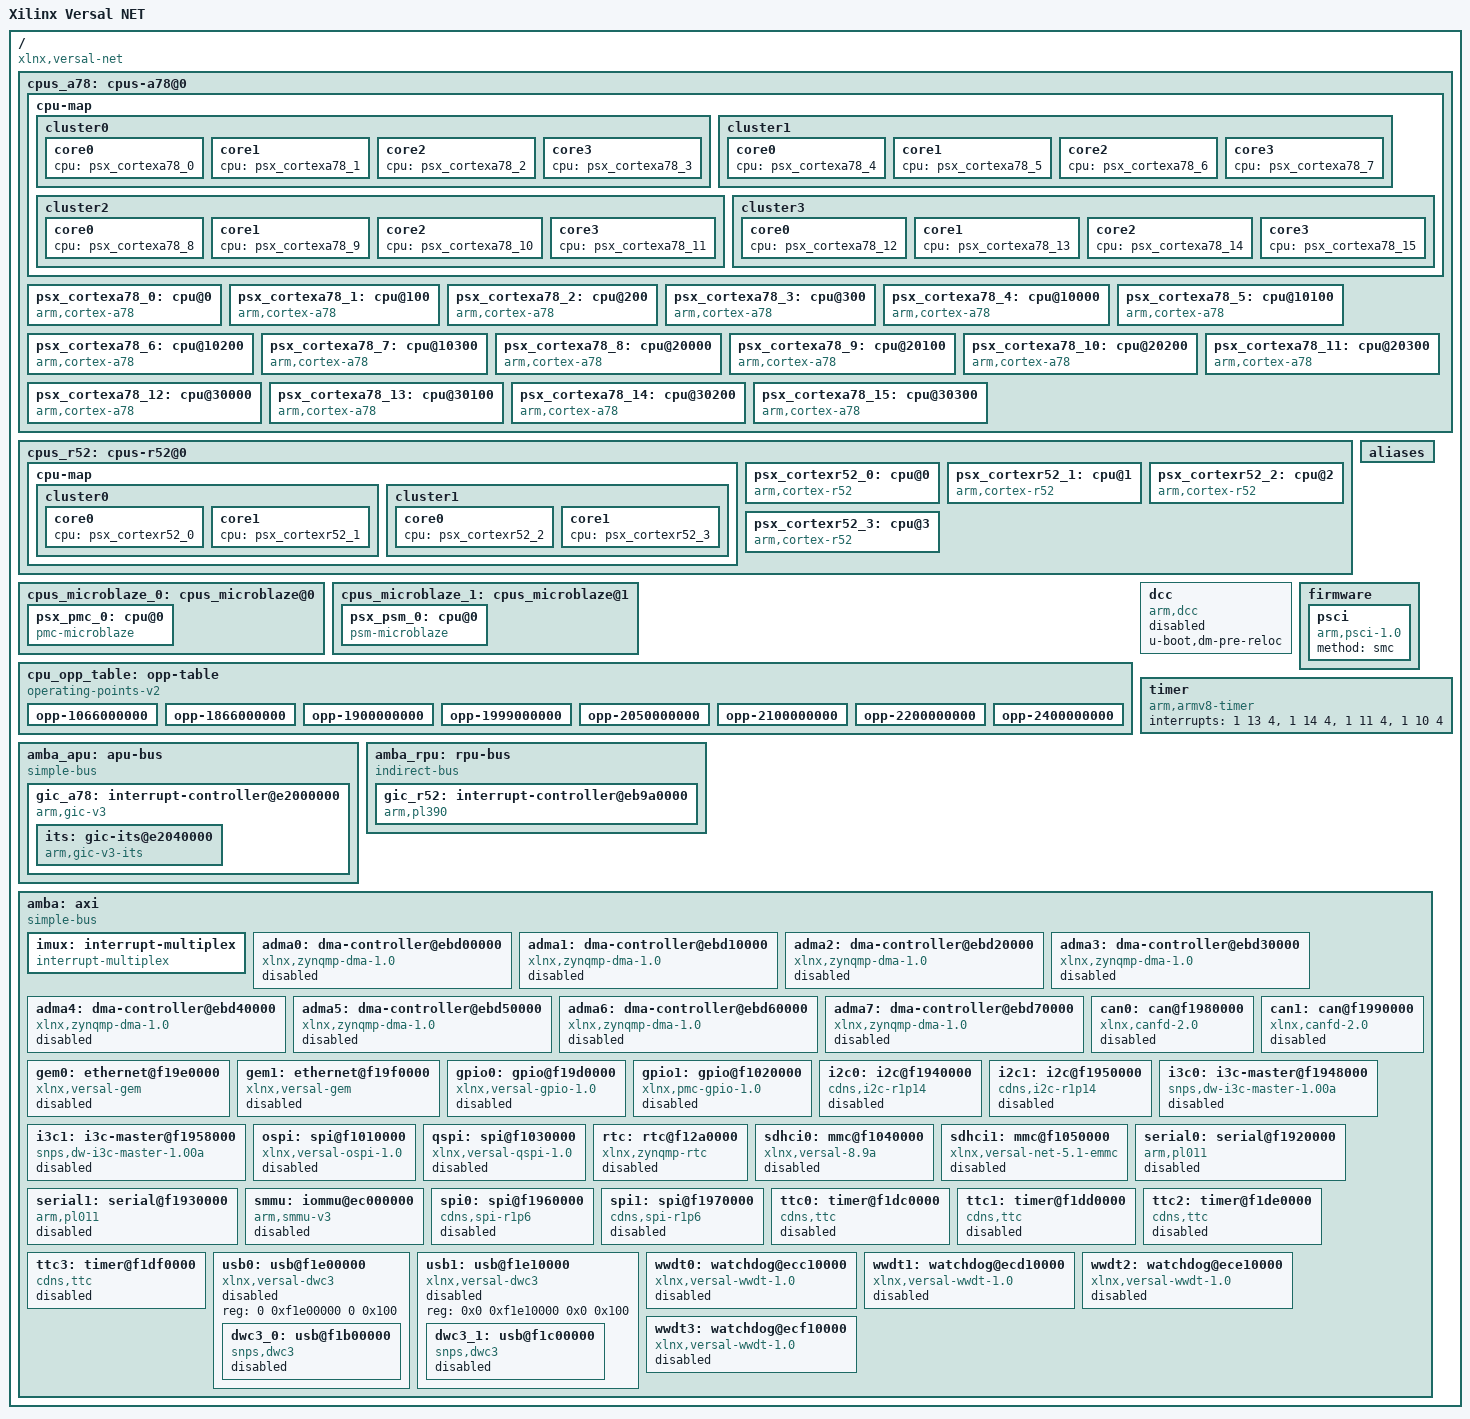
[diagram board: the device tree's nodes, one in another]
// SPDX-License-Identifier: GPL-2.0
/*
 * dts file for Xilinx Versal NET
 *
 * Copyright (C) 2022, Xilinx, Inc.
 * Copyright (C) 2022, Advanced Micro Devices, Inc.
 *
 * Michal Simek <michal.simek@amd.com>
 */

/ {
	compatible = "xlnx,versal-net";
	model = "Xilinx Versal NET";
	#address-cells = <2>;
	#size-cells = <2>;
	interrupt-parent = <&imux>;

	cpus_a78: cpus-a78@0 {
		#address-cells = <1>;
		#size-cells = <0>;
		cpu-map {
			cluster0 {
				core0 {
					cpu = <&psx_cortexa78_0>;
				};
				core1 {
					cpu = <&psx_cortexa78_1>;
				};
				core2 {
					cpu = <&psx_cortexa78_2>;
				};
				core3 {
					cpu = <&psx_cortexa78_3>;
				};
			};

			cluster1 {
				core0 {
					cpu = <&psx_cortexa78_4>;
				};

				core1 {
					cpu = <&psx_cortexa78_5>;
				};

				core2 {
					cpu = <&psx_cortexa78_6>;
				};

				core3 {
					cpu = <&psx_cortexa78_7>;
				};
			};
			cluster2 {
				core0 {
					cpu = <&psx_cortexa78_8>;
				};

				core1 {
					cpu = <&psx_cortexa78_9>;
				};

				core2 {
					cpu = <&psx_cortexa78_10>;
				};

				core3 {
					cpu = <&psx_cortexa78_11>;
				};
			};
			cluster3 {
				core0 {
					cpu = <&psx_cortexa78_12>;
				};

				core1 {
					cpu = <&psx_cortexa78_13>;
				};

				core2 {
					cpu = <&psx_cortexa78_14>;
				};

				core3 {
					cpu = <&psx_cortexa78_15>;
				};
			};

		};

		psx_cortexa78_0: cpu@0 {
			compatible = "arm,cortex-a78";
			device_type = "cpu";
			enable-method = "psci";
			reg = <0>;
            operating-points-v2 = <&cpu_opp_table>;
		};
		psx_cortexa78_1: cpu@100 {
			compatible = "arm,cortex-a78";
			device_type = "cpu";
			enable-method = "psci";
			reg = <0x100>;
            operating-points-v2 = <&cpu_opp_table>;
		};
		psx_cortexa78_2: cpu@200 {
			compatible = "arm,cortex-a78";
			device_type = "cpu";
			enable-method = "psci";
			reg = <0x200>;
            operating-points-v2 = <&cpu_opp_table>;
		};
		psx_cortexa78_3: cpu@300 {
			compatible = "arm,cortex-a78";
			device_type = "cpu";
			enable-method = "psci";
			reg = <0x300>;
            operating-points-v2 = <&cpu_opp_table>;
		};
		psx_cortexa78_4: cpu@10000 {
			compatible = "arm,cortex-a78";
			device_type = "cpu";
			enable-method = "psci";
			reg = <0x10000>;
            operating-points-v2 = <&cpu_opp_table>;
		};
		psx_cortexa78_5: cpu@10100 {
			compatible = "arm,cortex-a78";
			device_type = "cpu";
			enable-method = "psci";
			reg = <0x10100>;
            operating-points-v2 = <&cpu_opp_table>;
		};
		psx_cortexa78_6: cpu@10200 {
			compatible = "arm,cortex-a78";
			device_type = "cpu";
			enable-method = "psci";
			reg = <0x10200>;
            operating-points-v2 = <&cpu_opp_table>;
		};
		psx_cortexa78_7: cpu@10300 {
			compatible = "arm,cortex-a78";
			device_type = "cpu";
			enable-method = "psci";
			reg = <0x10300>;
            operating-points-v2 = <&cpu_opp_table>;
		};
		psx_cortexa78_8: cpu@20000 {
			compatible = "arm,cortex-a78";
			device_type = "cpu";
			enable-method = "psci";
			reg = <0x20000>;
            operating-points-v2 = <&cpu_opp_table>;
		};
		psx_cortexa78_9: cpu@20100 {
			compatible = "arm,cortex-a78";
			device_type = "cpu";
			enable-method = "psci";
			reg = <0x20100>;
            operating-points-v2 = <&cpu_opp_table>;
		};
		psx_cortexa78_10: cpu@20200 {
			compatible = "arm,cortex-a78";
			device_type = "cpu";
			enable-method = "psci";
			reg = <0x20200>;
            operating-points-v2 = <&cpu_opp_table>;
		};
		psx_cortexa78_11: cpu@20300 {
			compatible = "arm,cortex-a78";
			device_type = "cpu";
			enable-method = "psci";
			reg = <0x20300>;
            operating-points-v2 = <&cpu_opp_table>;
		};
		psx_cortexa78_12: cpu@30000 {
			compatible = "arm,cortex-a78";
			device_type = "cpu";
			enable-method = "psci";
			reg = <0x30000>;
            operating-points-v2 = <&cpu_opp_table>;
		};
		psx_cortexa78_13: cpu@30100 {
			compatible = "arm,cortex-a78";
			device_type = "cpu";
			enable-method = "psci";
			reg = <0x30100>;
            operating-points-v2 = <&cpu_opp_table>;
		};
		psx_cortexa78_14: cpu@30200 {
			compatible = "arm,cortex-a78";
			device_type = "cpu";
			enable-method = "psci";
			reg = <0x30200>;
            operating-points-v2 = <&cpu_opp_table>;
		};
		psx_cortexa78_15: cpu@30300 {
			compatible = "arm,cortex-a78";
			device_type = "cpu";
			enable-method = "psci";
			reg = <0x30300>;
            operating-points-v2 = <&cpu_opp_table>;
		};
	};

	cpus_r52: cpus-r52@0 {
		#address-cells = <1>;
		#size-cells = <0>;
		cpu-map {
			cluster0 {
				core0 {
					cpu = <&psx_cortexr52_0>;
				};
				core1 {
					cpu = <&psx_cortexr52_1>;
				};
			};

			cluster1 {
				core0 {
					cpu = <&psx_cortexr52_2>;
				};

				core1 {
					cpu = <&psx_cortexr52_3>;
				};
			};
		};

		psx_cortexr52_0: cpu@0 {
			compatible = "arm,cortex-r52";
			device_type = "cpu";
			reg = <0x0>;
			operating-points-v2 = <&cpu_opp_table>;
	    };

	    psx_cortexr52_1: cpu@1 {
			compatible = "arm,cortex-r52";
			device_type = "cpu";
			reg = <0x1>;
			operating-points-v2 = <&cpu_opp_table>;
		};

		psx_cortexr52_2: cpu@2 {
	        compatible = "arm,cortex-r52";
	        device_type = "cpu";
	        reg = <0x2>;
	        operating-points-v2 = <&cpu_opp_table>;
	    };

	    psx_cortexr52_3: cpu@3 {
	        compatible = "arm,cortex-r52";
	        device_type = "cpu";
	        reg = <0x3>;
	        operating-points-v2 = <&cpu_opp_table>;
	    };
	};

	cpus_microblaze_0: cpus_microblaze@0 {
		#address-cells = <1>;
		#size-cells = <0>;
        psx_pmc_0: cpu@0 {
            compatible = "pmc-microblaze";
            device_type = "cpu";
            reg = <0x0>;
            operating-points-v2 = <&cpu_opp_table>;
        };
	};

	cpus_microblaze_1: cpus_microblaze@1 {
		#address-cells = <1>;
		#size-cells = <0>;
        psx_psm_0: cpu@0 {
	        compatible = "psm-microblaze";
	        device_type = "cpu";
	        reg = <0x1>;
	        operating-points-v2 = <&cpu_opp_table>;
        };
	};


	cpu_opp_table: opp-table {
		compatible = "operating-points-v2";
		opp-1066000000 {
			opp-hz = /bits/ 64 <1066000000>;
			opp-microvolt = <1000000>;
			clock-latency-ns = <500000>;
		};
		opp-1866000000 {
			opp-hz = /bits/ 64 <1866000000>;
			opp-microvolt = <1000000>;
			clock-latency-ns = <500000>;
		};
		opp-1900000000 {
			opp-hz = /bits/ 64 <1900000000>;
			opp-microvolt = <1000000>;
			clock-latency-ns = <500000>;
		};
		opp-1999000000 {
			opp-hz = /bits/ 64 <1999000000>;
			opp-microvolt = <1000000>;
			clock-latency-ns = <500000>;
		};
		opp-2050000000 {
			opp-hz = /bits/ 64 <2050000000>;
			opp-microvolt = <1000000>;
			clock-latency-ns = <500000>;
		};
		opp-2100000000 {
			opp-hz = /bits/ 64 <2100000000>;
			opp-microvolt = <1000000>;
			clock-latency-ns = <500000>;
		};
		opp-2200000000 {
			opp-hz = /bits/ 64 <2200000000>;
			opp-microvolt = <1000000>;
			clock-latency-ns = <500000>;
		};
		opp-2400000000 {
			opp-hz = /bits/ 64 <2400000000>;
			opp-microvolt = <1000000>;
			clock-latency-ns = <500000>;
        };
    };
	aliases {
		serial0 = &serial0;
		serial1 = &serial1;
		serial2 = &dcc;
		mmc0 = &sdhci0;
		mmc1 = &sdhci1;
		i2c0 = &i2c0;
		i2c1 = &i2c1;
		rtc = &rtc;
		usb0 = &usb0;
		usb1 = &usb1;
		spi0 = &ospi;
		spi1 = &qspi;
	};

	dcc: dcc {
		compatible = "arm,dcc";
		status = "disabled";
		u-boot,dm-pre-reloc;
	};

	firmware {
		psci {
			compatible = "arm,psci-1.0";
			method = "smc";
		};
	};

	timer: timer {
		compatible = "arm,armv8-timer";
		interrupts = <1 13 4>, <1 14 4>, <1 11 4>, <1 10 4>; /* FIXME 3rd cell */
	};

	amba_apu: apu-bus {
		compatible = "simple-bus";
		#address-cells = <2>;
		#size-cells = <2>;
		ranges;
		interrupt-parent = <&gic_a78>;
		u-boot,dm-pre-reloc;

		gic_a78: interrupt-controller@e2000000 {
			compatible = "arm,gic-v3";
			#interrupt-cells = <3>;
			#address-cells = <2>;
			#size-cells = <2>;
			ranges;
			reg = <0 0xe2000000 0 0x10000>,
			      <0 0xe2060000 0 0x200000>;
			interrupt-controller;
			interrupt-parent = <&gic_a78>;
			interrupts = <1 9 4>;

			its: gic-its@e2040000 {
				compatible = "arm,gic-v3-its";
				msi-controller;
				msi-cells = <1>;
				reg = <0 0xe2040000 0 0x20000>;
		        };
		};
	};

	amba_rpu: rpu-bus {
		compatible = "indirect-bus";
		#address-cells = <0x2>;
		#size-cells = <0x2>;
		ranges;
		interrupt-parent = <&gic_r52>;
		u-boot,dm-pre-reloc;

		gic_r52: interrupt-controller@eb9a0000 {
			compatible = "arm,pl390";
			#interrupt-cells = <3>;
			interrupt-controller;
			reg = <0x0 0xeb9a0000 0x0 0x1000>;
		};
	};



	amba: axi {
		compatible = "simple-bus";
		u-boot,dm-pre-reloc;
		#address-cells = <2>;
		#size-cells = <2>;
		ranges;
		interrupt-parent = <&imux>;

		/* Proxy Interrupt Controller */
		imux: interrupt-multiplex {
			compatible = "interrupt-multiplex";
			#address-cells = <0x0>;
			#interrupt-cells = <3>;
			interrupt-controller;
			interrupt-parent = <&gic_a78>, <&gic_r52>;
			/* mask for address cells, mask for interrupt cells of the children */
			interrupt-map-mask = <0x0 0xffff 0x0>;
			/* 1:1 mapping of all interrupts to gic_a78 and gic_r52 */
			/* child address cells, child interrupt cells, parent, parent interrupt cells */
			interrupt-map = <0x0 0x14 0x0 &gic_a78 0x0 0x14 0x4>,
					<0x0 0x15 0x0 &gic_a78 0x0 0x15 0x4>,
					<0x0 0x16 0x0 &gic_a78 0x0 0x16 0x4>,
					<0x0 0x17 0x0 &gic_a78 0x0 0x17 0x4>,
					<0x0 0x18 0x0 &gic_a78 0x0 0x18 0x4>,
					<0x0 0x19 0x0 &gic_a78 0x0 0x19 0x4>,
					<0x0 0x1a 0x0 &gic_a78 0x0 0x1a 0x4>,
					<0x0 0x1b 0x0 &gic_a78 0x0 0x1b 0x4>,
					<0x0 0x1c 0x0 &gic_a78 0x0 0x1c 0x4>,
					<0x0 0x1d 0x0 &gic_a78 0x0 0x1d 0x4>,
					<0x0 0x21 0x0 &gic_a78 0x0 0x21 0x4>,
					<0x0 0x22 0x0 &gic_a78 0x0 0x22 0x4>,
					<0x0 0x26 0x0 &gic_a78 0x0 0x26 0x4>,
					<0x0 0x27 0x0 &gic_a78 0x0 0x27 0x4>,
					<0x0 0x29 0x0 &gic_a78 0x0 0x29 0x4>,
					<0x0 0x2b 0x0 &gic_a78 0x0 0x2b 0x4>,
					<0x0 0x2c 0x0 &gic_a78 0x0 0x2c 0x4>,
					<0x0 0x2d 0x0 &gic_a78 0x0 0x2d 0x4>,
					<0x0 0x2e 0x0 &gic_a78 0x0 0x2e 0x4>,
					<0x0 0x2f 0x0 &gic_a78 0x0 0x2f 0x4>,
					<0x0 0x30 0x0 &gic_a78 0x0 0x30 0x4>,
					<0x0 0x31 0x0 &gic_a78 0x0 0x31 0x4>,
					<0x0 0x32 0x0 &gic_a78 0x0 0x32 0x4>,
					<0x0 0x33 0x0 &gic_a78 0x0 0x33 0x4>,
					<0x0 0x34 0x0 &gic_a78 0x0 0x34 0x4>,
					<0x0 0x35 0x0 &gic_a78 0x0 0x35 0x4>,
					<0x0 0x36 0x0 &gic_a78 0x0 0x36 0x4>,
					<0x0 0x48 0x0 &gic_a78 0x0 0x48 0x4>,
					<0x0 0x49 0x0 &gic_a78 0x0 0x49 0x4>,
					<0x0 0x4a 0x0 &gic_a78 0x0 0x4a 0x4>,
					<0x0 0x4b 0x0 &gic_a78 0x0 0x4b 0x4>,
					<0x0 0x4c 0x0 &gic_a78 0x0 0x4c 0x4>,
					<0x0 0x4d 0x0 &gic_a78 0x0 0x4d 0x4>,
					<0x0 0x4e 0x0 &gic_a78 0x0 0x4e 0x4>,
					<0x0 0x4f 0x0 &gic_a78 0x0 0x4f 0x4>,
					<0x0 0x62 0x0 &gic_a78 0x0 0x62 0x4>,
					<0x0 0x63 0x0 &gic_a78 0x0 0x63 0x4>,
					<0x0 0xa9 0x0 &gic_a78 0x0 0xa9 0x4>,
					<0x0 0xb4 0x0 &gic_a78 0x0 0xb4 0x4>,
					<0x0 0xb5 0x0 &gic_a78 0x0 0xb5 0x4>,
					<0x0 0xb6 0x0 &gic_a78 0x0 0xb6 0x4>,
					<0x0 0xb7 0x0 &gic_a78 0x0 0xb7 0x4>,
					<0x0 0xb9 0x0 &gic_a78 0x0 0xb9 0x4>,
					<0x0 0xc8 0x0 &gic_a78 0x0 0xc8 0x4>,
					<0x0 0xc9 0x0 &gic_a78 0x0 0xc9 0x4>,
					<0x0 0x8b 0x0 &gic_a78 0x0 0x8b 0x1>,
					<0x0 0x8c 0x0 &gic_a78 0x0 0x8c 0x1>,
					<0x0 0x8f 0x0 &gic_a78 0x0 0x8f 0x1>,
					<0x0 0x90 0x0 &gic_a78 0x0 0x90 0x1>,
					<0x0 0x93 0x0 &gic_a78 0x0 0x93 0x1>,
					<0x0 0x94 0x0 &gic_a78 0x0 0x94 0x1>,
					<0x0 0xa4 0x0 &gic_a78 0x0 0xa4 0x1>,
					<0x0 0xa5 0x0 &gic_a78 0x0 0xa5 0x1>,
					<0x0 0x14 0x0 &gic_r52 0x0 0x14 0x4>,
					<0x0 0x15 0x0 &gic_r52 0x0 0x15 0x4>,
					<0x0 0x16 0x0 &gic_r52 0x0 0x16 0x4>,
					<0x0 0x17 0x0 &gic_r52 0x0 0x17 0x4>,
					<0x0 0x18 0x0 &gic_r52 0x0 0x18 0x4>,
					<0x0 0x19 0x0 &gic_r52 0x0 0x19 0x4>,
					<0x0 0x1a 0x0 &gic_r52 0x0 0x1a 0x4>,
					<0x0 0x1b 0x0 &gic_r52 0x0 0x1b 0x4>,
					<0x0 0x1c 0x0 &gic_r52 0x0 0x1c 0x4>,
					<0x0 0x1d 0x0 &gic_r52 0x0 0x1d 0x4>,
					<0x0 0x21 0x0 &gic_r52 0x0 0x21 0x4>,
					<0x0 0x22 0x0 &gic_r52 0x0 0x22 0x4>,
					<0x0 0x26 0x0 &gic_r52 0x0 0x26 0x4>,
					<0x0 0x27 0x0 &gic_r52 0x0 0x27 0x4>,
					<0x0 0x29 0x0 &gic_r52 0x0 0x29 0x4>,
					<0x0 0x2b 0x0 &gic_r52 0x0 0x2b 0x4>,
					<0x0 0x2c 0x0 &gic_r52 0x0 0x2c 0x4>,
					<0x0 0x2d 0x0 &gic_r52 0x0 0x2d 0x4>,
					<0x0 0x2e 0x0 &gic_r52 0x0 0x2e 0x4>,
					<0x0 0x2f 0x0 &gic_r52 0x0 0x2f 0x4>,
					<0x0 0x30 0x0 &gic_r52 0x0 0x30 0x4>,
					<0x0 0x31 0x0 &gic_r52 0x0 0x31 0x4>,
					<0x0 0x32 0x0 &gic_r52 0x0 0x32 0x4>,
					<0x0 0x33 0x0 &gic_r52 0x0 0x33 0x4>,
					<0x0 0x34 0x0 &gic_r52 0x0 0x34 0x4>,
					<0x0 0x35 0x0 &gic_r52 0x0 0x35 0x4>,
					<0x0 0x36 0x0 &gic_r52 0x0 0x36 0x4>,
					<0x0 0x48 0x0 &gic_r52 0x0 0x48 0x4>,
					<0x0 0x49 0x0 &gic_r52 0x0 0x49 0x4>,
					<0x0 0x4a 0x0 &gic_r52 0x0 0x4a 0x4>,
					<0x0 0x4b 0x0 &gic_r52 0x0 0x4b 0x4>,
					<0x0 0x4c 0x0 &gic_r52 0x0 0x4c 0x4>,
					<0x0 0x4d 0x0 &gic_r52 0x0 0x4d 0x4>,
					<0x0 0x4e 0x0 &gic_r52 0x0 0x4e 0x4>,
					<0x0 0x4f 0x0 &gic_r52 0x0 0x4f 0x4>,
					<0x0 0x62 0x0 &gic_r52 0x0 0x62 0x4>,
					<0x0 0x63 0x0 &gic_r52 0x0 0x63 0x4>,
					<0x0 0xa9 0x0 &gic_r52 0x0 0xa9 0x4>,
					<0x0 0xb4 0x0 &gic_r52 0x0 0xb4 0x4>,
					<0x0 0xb5 0x0 &gic_r52 0x0 0xb5 0x4>,
					<0x0 0xb6 0x0 &gic_r52 0x0 0xb6 0x4>,
					<0x0 0xb7 0x0 &gic_r52 0x0 0xb7 0x4>,
					<0x0 0xb9 0x0 &gic_r52 0x0 0xb9 0x4>,
					<0x0 0xc8 0x0 &gic_r52 0x0 0xc8 0x4>,
					<0x0 0xc9 0x0 &gic_r52 0x0 0xc9 0x4>,
					<0x0 0x8b 0x0 &gic_r52 0x0 0x8b 0x1>,
					<0x0 0x8c 0x0 &gic_r52 0x0 0x8c 0x1>,
					<0x0 0x8f 0x0 &gic_r52 0x0 0x8f 0x1>,
					<0x0 0x90 0x0 &gic_r52 0x0 0x90 0x1>,
					<0x0 0x93 0x0 &gic_r52 0x0 0x93 0x1>,
					<0x0 0x94 0x0 &gic_r52 0x0 0x94 0x1>,
					<0x0 0xa4 0x0 &gic_r52 0x0 0xa4 0x1>,
					<0x0 0xa5 0x0 &gic_r52 0x0 0xa5 0x1>;
		};


		adma0: dma-controller@ebd00000 {
			compatible = "xlnx,zynqmp-dma-1.0";
			status = "disabled";
			reg = <0 0xebd00000 0 0x1000>;
			interrupt-parent = <&imux>;
			interrupts = <0 72 4>;
			clock-names = "clk_main", "clk_apb";
			#dma-cells = <1>;
			xlnx,bus-width = <64>;
		};

		adma1: dma-controller@ebd10000 {
			compatible = "xlnx,zynqmp-dma-1.0";
			status = "disabled";
			reg = <0 0xebd10000 0 0x1000>;
			interrupt-parent = <&imux>;
			interrupts = <0 73 4>;
			clock-names = "clk_main", "clk_apb";
			#dma-cells = <1>;
			xlnx,bus-width = <64>;
		};

		adma2: dma-controller@ebd20000 {
			compatible = "xlnx,zynqmp-dma-1.0";
			status = "disabled";
			reg = <0 0xebd20000 0 0x1000>;
			interrupt-parent = <&imux>;
			interrupts = <0 74 4>;
			clock-names = "clk_main", "clk_apb";
			#dma-cells = <1>;
			xlnx,bus-width = <64>;
		};

		adma3: dma-controller@ebd30000 {
			compatible = "xlnx,zynqmp-dma-1.0";
			status = "disabled";
			reg = <0 0xebd30000 0 0x1000>;
			interrupt-parent = <&imux>;
			interrupts = <0 75 4>;
			clock-names = "clk_main", "clk_apb";
			#dma-cells = <1>;
			xlnx,bus-width = <64>;
		};

		adma4: dma-controller@ebd40000 {
			compatible = "xlnx,zynqmp-dma-1.0";
			status = "disabled";
			reg = <0 0xebd40000 0 0x1000>;
			interrupt-parent = <&imux>;
			interrupts = <0 76 4>;
			clock-names = "clk_main", "clk_apb";
			#dma-cells = <1>;
			xlnx,bus-width = <64>;
		};

		adma5: dma-controller@ebd50000 {
			compatible = "xlnx,zynqmp-dma-1.0";
			status = "disabled";
			reg = <0 0xebd50000 0 0x1000>;
			interrupt-parent = <&imux>;
			interrupts = <0 77 4>;
			clock-names = "clk_main", "clk_apb";
			#dma-cells = <1>;
			xlnx,bus-width = <64>;
		};

		adma6: dma-controller@ebd60000 {
			compatible = "xlnx,zynqmp-dma-1.0";
			status = "disabled";
			reg = <0 0xebd60000 0 0x1000>;
			interrupt-parent = <&imux>;
			interrupts = <0 78 4>;
			clock-names = "clk_main", "clk_apb";
			#dma-cells = <1>;
			xlnx,bus-width = <64>;
		};

		adma7: dma-controller@ebd70000 {
			compatible = "xlnx,zynqmp-dma-1.0";
			status = "disabled";
			reg = <0 0xebd70000 0 0x1000>;
			interrupt-parent = <&imux>;
			interrupts = <0 79 4>;
			clock-names = "clk_main", "clk_apb";
			#dma-cells = <1>;
			xlnx,bus-width = <64>;
		};

		can0: can@f1980000 {
			compatible = "xlnx,canfd-2.0";
			status = "disabled";
			reg = <0 0xf1980000 0 0x6000>;
			interrupt-parent = <&imux>;
			interrupts = <0 27 4>;
			clock-names = "can_clk", "s_axi_aclk";
			rx-fifo-depth = <64>;
			tx-mailbox-count = <32>;
		};

		can1: can@f1990000 {
			compatible = "xlnx,canfd-2.0";
			status = "disabled";
			reg = <0 0xf1990000 0 0x6000>;
			interrupt-parent = <&imux>;
			interrupts = <0 28 4>;
			clock-names = "can_clk", "s_axi_aclk";
			rx-fifo-depth = <64>;
			tx-mailbox-count = <32>;
		};

		gem0: ethernet@f19e0000 {
			compatible = "xlnx,versal-gem", "cdns,gem";
			status = "disabled";
			reg = <0 0xf19e0000 0 0x1000>;
			interrupt-parent = <&imux>;
			interrupts = <0 39 4>, <0 39 4>;
			clock-names = "pclk", "hclk", "tx_clk", "rx_clk",
			              "tsu_clk";
		};

		gem1: ethernet@f19f0000 {
			compatible = "xlnx,versal-gem", "cdns,gem";
			status = "disabled";
			reg = <0 0xf19f0000 0 0x1000>;
			interrupt-parent = <&imux>;
			interrupts = <0 41 4>, <0 41 4>;
			clock-names = "pclk", "hclk", "tx_clk", "rx_clk",
				      "tsu_clk";
		};

		gpio0: gpio@f19d0000 {
			compatible = "xlnx,versal-gpio-1.0";
			status = "disabled";
			reg = <0 0xf19d0000 0 0x1000>;
			interrupt-parent = <&imux>;
			interrupts = <0 20 4>;
			#gpio-cells = <2>;
			gpio-controller;
			#interrupt-cells = <2>;
			interrupt-controller;
		};

		gpio1: gpio@f1020000 {
			compatible = "xlnx,pmc-gpio-1.0";
			status = "disabled";
			reg = <0 0xf1020000 0 0x1000>;
			interrupt-parent = <&imux>;
			interrupts = <0 180 4>;
			#gpio-cells = <2>;
			gpio-controller;
			#interrupt-cells = <2>;
			interrupt-controller;
		};

		i2c0: i2c@f1940000 {
			compatible = "cdns,i2c-r1p14";
			status = "disabled";
			reg = <0 0xf1940000 0 0x1000>;
			interrupt-parent = <&imux>;
			interrupts = <0 21 4>;
			clock-frequency = <400000>;
			#address-cells = <1>;
			#size-cells = <0>;
		};

		i2c1: i2c@f1950000 {
			compatible = "cdns,i2c-r1p14";
			status = "disabled";
			reg = <0 0xf1950000 0 0x1000>;
			interrupt-parent = <&imux>;
			interrupts = <0 22 4>;
			clock-frequency = <400000>;
			#address-cells = <1>;
			#size-cells = <0>;
		};

		i3c0: i3c-master@f1948000 {
			compatible = "snps,dw-i3c-master-1.00a";
			status = "disabled";
			reg = <0 0xf1948000 0 0x1000>;
			#address-cells = <3>;
			#size-cells = <0>;
			interrupt-parent = <&imux>;
			interrupts = <0 21 4>;
		};

		i3c1: i3c-master@f1958000 {
			compatible = "snps,dw-i3c-master-1.00a";
			status = "disabled";
			reg = <0 0xf1958000 0 0x1000>;
			#address-cells = <3>;
			#size-cells = <0>;
			interrupt-parent = <&imux>;
			interrupts = <0 22 4>;
		};

		ospi: spi@f1010000 {
			compatible = "xlnx,versal-ospi-1.0", "cdns,qspi-nor";
			status = "disabled";
			reg = <0 0xf1010000 0 0x10000>,
			      <0 0xc0000000 0 0x20000000>;
			interrupt-parent = <&imux>;
			interrupts = <0 182 4>;
			cdns,fifo-depth = <256>;
			cdns,fifo-width = <4>;
			cdns,is-dma = <1>; /* u-boot specific */
			/* cdns,is-stig-pgm = <1>; - unused - checking with Sai */
			cdns,trigger-address = <0xc0000000>;
		};

		qspi: spi@f1030000 {
			compatible = "xlnx,versal-qspi-1.0";
			status = "disabled";
			reg = <0 0xf1030000 0 0x1000>; /* missing one more reg range - checking with Sai */
			interrupt-parent = <&imux>;
			interrupts = <0 183 4>;
			clock-names = "ref_clk", "pclk";
		};

		rtc: rtc@f12a0000 {
			compatible = "xlnx,zynqmp-rtc";
			status = "disabled";
			reg = <0 0xf12a0000 0 0x100>;
			interrupt-parent = <&imux>;
			interrupts = <0 200 4>, <0 201 4>;
			interrupt-names = "alarm", "sec";
			calibration = <0x8000>;
		};

		sdhci0: mmc@f1040000 {
			compatible = "xlnx,versal-8.9a", "arasan,sdhci-8.9a";
			status = "disabled";
			reg = <0 0xf1040000 0 0x10000>;
			interrupt-parent = <&imux>;
			interrupts = <0 184 4>;
			clock-names = "clk_xin", "clk_ahb", "gate";
			#clock-cells = <1>;
			clock-output-names = "clk_out_sd0", "clk_in_sd0";
		};

		sdhci1: mmc@f1050000 {
			compatible = "xlnx,versal-net-5.1-emmc",
				     "arasan,sdhci-8.9a";
			status = "disabled";
			reg = <0 0xf1050000 0 0x10000>;
			interrupt-parent = <&imux>;
			interrupts = <0 186 4>;
			clock-names = "clk_xin", "clk_ahb", "gate";
			#clock-cells = <1>;
			clock-output-names = "clk_out_sd1", "clk_in_sd1";
		};

		serial0: serial@f1920000 {
			u-boot,dm-pre-reloc;
			compatible = "arm,pl011", "arm,primecell";
			status = "disabled";
			reg = <0 0xf1920000 0 0x1000>;
			interrupt-parent = <&imux>;
			interrupts = <0 25 4>;
			reg-io-width = <4>;
			clock-names = "uartclk", "apb_pclk";
			current-speed = <115200>;
		};

		serial1: serial@f1930000 {
			u-boot,dm-pre-reloc;
			compatible = "arm,pl011", "arm,primecell";
			status = "disabled";
			reg = <0 0xf1930000 0 0x1000>;
			interrupt-parent = <&imux>;
			interrupts = <0 26 4>;
			reg-io-width = <4>;
			clock-names = "uartclk", "apb_pclk";
			current-speed = <115200>;
		};

		smmu: iommu@ec000000 {
			compatible = "arm,smmu-v3";
			status = "disabled";
			reg = <0 0xec000000 0 0x40000>;
			#iommu-cells = <1>;
			interrupt-names = "combined";
			interrupt-parent = <&imux>;
			interrupts = <0 169 4>;
			dma-coherent;
		};

		spi0: spi@f1960000 {
			compatible = "cdns,spi-r1p6";
			status = "disabled";
			interrupt-parent = <&imux>;
			interrupts = <0 23 4>;
			reg = <0 0xf1960000 0 0x1000>;
			clock-names = "ref_clk", "pclk";
		};

		spi1: spi@f1970000 {
			compatible = "cdns,spi-r1p6";
			status = "disabled";
			interrupt-parent = <&imux>;
			interrupts = <0 24 4>;
			reg = <0 0xf1970000 0 0x1000>;
			clock-names = "ref_clk", "pclk";
		};

		ttc0: timer@f1dc0000 {
			compatible = "cdns,ttc";
			status = "disabled";
			interrupt-parent = <&imux>;
			interrupts = <0 43 4>, <0 44 4>, <0 45 4>;
			timer-width = <32>;
			reg = <0x0 0xf1dc0000 0x0 0x1000>;
		};

		ttc1: timer@f1dd0000 {
			compatible = "cdns,ttc";
			status = "disabled";
			interrupt-parent = <&imux>;
			interrupts = <0 46 4>, <0 47 4>, <0 48 4>;
			timer-width = <32>;
			reg = <0x0 0xf1dd0000 0x0 0x1000>;
		};

		ttc2: timer@f1de0000 {
			compatible = "cdns,ttc";
			status = "disabled";
			interrupt-parent = <&imux>;
			interrupts = <0 49 4>, <0 50 4>, <0 51 4>;
			timer-width = <32>;
			reg = <0x0 0xf1de0000 0x0 0x1000>;
		};

		ttc3: timer@f1df0000 {
			compatible = "cdns,ttc";
			status = "disabled";
			interrupt-parent = <&imux>;
			interrupts = <0 52 4>, <0 53 4>, <0 54 4>;
			timer-width = <32>;
			reg = <0x0 0xf1df0000 0x0 0x1000>;
		};

		usb0: usb@f1e00000 {
			compatible = "xlnx,versal-dwc3";
			status = "disabled";
			reg = <0 0xf1e00000 0 0x100>;
			clock-names = "bus_clk", "ref_clk";
			ranges;
			#address-cells = <2>;
			#size-cells = <2>;

			dwc3_0: usb@f1b00000  {
				compatible = "snps,dwc3";
				status = "disabled";
				reg = <0 0xf1b00000 0 0x10000>;
				interrupt-names = "dwc_usb3", "otg", "usb-wakeup";
				interrupt-parent = <&imux>;
				interrupts = <0 29 4>, <0 33 4>, <0 98 4>;
				snps,dis_u2_susphy_quirk;
				snps,dis_u3_susphy_quirk;
				snps,quirk-frame-length-adjustment = <0x20>;
				dr_mode = "peripheral";
				maximum-speed = "high-speed";
				snps,usb3_lpm_capable;
				/*phy-names = "usb3-phy";- checking with Pyiush */
			};
		};

		usb1: usb@f1e10000 {
			compatible = "xlnx,versal-dwc3";
			status = "disabled";
			reg = <0x0 0xf1e10000 0x0 0x100>;
			clock-names = "bus_clk", "ref_clk";
			ranges;
			#address-cells = <2>;
			#size-cells = <2>;

			dwc3_1: usb@f1c00000  {
				compatible = "snps,dwc3";
				status = "disabled";
				reg = <0x0 0xf1c00000 0x0 0x10000>;
				interrupt-names = "dwc_usb3","otg","usb-wakeup";
				interrupt-parent = <&imux>;
				interrupts = <0 34 4>, <0 38 4>, <0 99 4>;
				snps,dis_u2_susphy_quirk;
				snps,dis_u3_susphy_quirk;
				snps,quirk-frame-length-adjustment = <0x20>;
				dr_mode = "host";
				maximum-speed = "high-speed";
				snps,usb3_lpm_capable;
				/* phy-names = "usb3-phy"; - checking with Pyiush */
			};
		};

		wwdt0: watchdog@ecc10000 {
			compatible = "xlnx,versal-wwdt-1.0";
			status = "disabled";
			reg = <0 0xecc10000 0 0x10000>;
			interrupt-names = "wdt", "wwdt_reset_pending";
			interrupt-parent = <&imux>;
			interrupts = <0 139 1>, <0 140 1>;
			timeout-sec = <30>;
			pretimeout-sec = <25>;
		};

		wwdt1: watchdog@ecd10000 {
			compatible = "xlnx,versal-wwdt-1.0";
			status = "disabled";
			reg = <0 0xecd10000 0 0x10000>;
			interrupt-names = "wdt", "wwdt_reset_pending";
			interrupt-parent = <&imux>;
			interrupts = <0 143 1>, <0 144 1>;
			timeout-sec = <30>;
			pretimeout-sec = <25>;
		};

		wwdt2: watchdog@ece10000 {
			compatible = "xlnx,versal-wwdt-1.0";
			status = "disabled";
			reg = <0 0xece10000 0 0x10000>;
			interrupt-names = "wdt", "wwdt_reset_pending";
			interrupt-parent = <&imux>;
			interrupts = <0 147 1>,  <0 148 1>;
			timeout-sec = <30>;
			pretimeout-sec = <25>;
		};

		wwdt3: watchdog@ecf10000 {
			compatible = "xlnx,versal-wwdt-1.0";
			status = "disabled";
			reg = <0 0xecf10000 0 0x10000>;
			interrupt-names = "wdt", "wwdt_reset_pending";
			interrupt-parent = <&imux>;
			interrupts = <0 164 1>, <0 165 1>;
			timeout-sec = <30>;
			pretimeout-sec = <25>;
		};
	};
};
